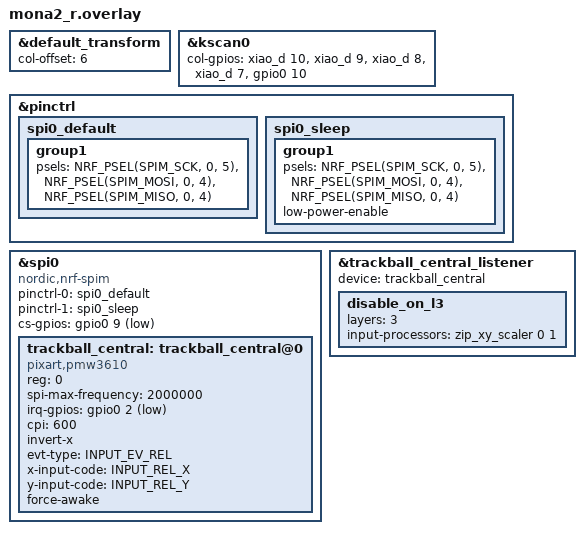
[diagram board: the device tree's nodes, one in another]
#include "mona2.dtsi"
#include <input/processors.dtsi>
#include <zephyr/dt-bindings/input/input-event-codes.h>


&default_transform {
    col-offset = <6>;
};

&kscan0 {
        col-gpios
            = <&xiao_d 10 GPIO_ACTIVE_HIGH>
            , <&xiao_d 9 GPIO_ACTIVE_HIGH> 
            , <&xiao_d 8 GPIO_ACTIVE_HIGH> 
            , <&xiao_d 7 GPIO_ACTIVE_HIGH> 
            , <&gpio0 10 GPIO_ACTIVE_HIGH>
            ;
};


&pinctrl {
    spi0_default: spi0_default {    //通常時(SPI通信中)のピン構成
        group1 {
            psels = <NRF_PSEL(SPIM_SCK, 0, 5)>, //P0.05を指定(SCLK)
                <NRF_PSEL(SPIM_MOSI, 0, 4)>,    //P0.04を指定(SDIOだからMOSI,MISO両方の役割を担う)
                <NRF_PSEL(SPIM_MISO, 0, 4)>;
        };
    };

    spi0_sleep: spi0_sleep {    //スリープ時のピン構成(省電力)
        group1 {
            psels = <NRF_PSEL(SPIM_SCK, 0, 5)>,
                <NRF_PSEL(SPIM_MOSI, 0, 4)>,
                <NRF_PSEL(SPIM_MISO, 0, 4)>;
            low-power-enable;
        };
    };
};


&spi0 {
    status = "okay";
    compatible = "nordic,nrf-spim"; //マイコンがnRFシリーズ
    pinctrl-0 = <&spi0_default>;
    pinctrl-1 = <&spi0_sleep>;
    pinctrl-names = "default", "sleep";
    cs-gpios = <&gpio0 9 GPIO_ACTIVE_LOW>;  //P0.09を指定(CS)

    trackball_central: trackball_central@0 {
        status = "okay";
        compatible = "pixart,pmw3610";  //トラボセンサ用のドライバとバインド
        reg = <0>;
        spi-max-frequency = <2000000>;
        irq-gpios = <&gpio0 2 (GPIO_ACTIVE_LOW | GPIO_PULL_UP)>; //P0.02を指定(MOTION)
        cpi = <600>;
        //swap-xy;
        invert-x; //COROPIT版ではコメントアウトを外す
        //invert-y; //COROPIT版ではコメントアウトを外す
        evt-type = <INPUT_EV_REL>;
        x-input-code = <INPUT_REL_X>;
        y-input-code = <INPUT_REL_Y>;
        force-awake; // ZMKがアクティブな間センサーを起きたままにする
    };
};

/*
&zip_temp_layer {
    excluded-positions = <38>;  // MOUSEレイヤーのクリックキー(38:&mkp MB1)。押してもAMLを解除しない
    require-prior-idle-ms = <300>;  // 好きなmsに調整（例: 300ms）
};
*/

// Overrides for the input listener node
&trackball_central_listener {
    status = "okay";
    device = <&trackball_central>;

    //input-processors = <&zip_temp_layer 5 10000>; // AML無効化

    disable_on_l3 {
        layers = <3>;
        input-processors = <&zip_xy_scaler 0 1>;    //移動量を0倍にしてトラックボールを無効化
    };

};
